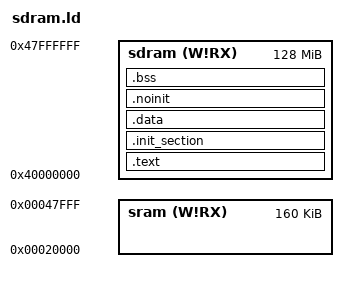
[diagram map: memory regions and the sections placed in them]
/****************************************************************************
 * boards/arm/t113/t113-evb/scripts/sdram.ld.S
 *
 * SPDX-License-Identifier: Apache-2.0
 *
 * Licensed to the Apache Software Foundation (ASF) under one or more
 * contributor license agreements.  See the NOTICE file distributed with
 * this work for additional information regarding copyright ownership.  The
 * ASF licenses this file to you under the Apache License, Version 2.0 (the
 * "License"); you may not use this file except in compliance with the
 * License.  You may obtain a copy of the License at
 *
 *   http://www.apache.org/licenses/LICENSE-2.0
 *
 * Unless required by applicable law or agreed to in writing, software
 * distributed under the License is distributed on an "AS IS" BASIS, WITHOUT
 * WARRANTIES OR CONDITIONS OF ANY KIND, either express or implied.  See the
 * License for the specific language governing permissions and limitations
 * under the License.
 *
 ****************************************************************************/

/* T113-S3 DDR linker script for NuttX AP binary.
 *
 * Standard layout: vectors at CONFIG_RAM_START (0x40000000), __start entry.
 * This binary is loaded to DDR by boot0 or xfel, no eGON header.
 */

MEMORY
{
    /* T113-S3 on-chip SRAM: 160KB (SRAM_A1 32K + DSP IRAM 64K + DSP DRAM0 32K + DSP DRAM1 32K)
     * Available at reset (DSP SRAM remapped to CPU by default).
     * Reserved for future use — no sections placed here yet.
     */
    sram  (W!RX) : ORIGIN = 0x00020000, LENGTH = 160K

    /* External DDR: 128MB at 0x40000000 */
    sdram (W!RX) : ORIGIN = 0x40000000, LENGTH = 128M
}

OUTPUT_FORMAT("elf32-littlearm", "elf32-littlearm", "elf32-littlearm")
OUTPUT_ARCH(arm)
ENTRY(_stext)

SECTIONS
{
    .text :
    {
        _stext = ABSOLUTE(.);
        *(.vectors)
        *(.text .text.*)
        *(.fixup)
        *(.gnu.warning)
        *(.rodata .rodata.*)
        *(.gnu.linkonce.t.*)
        *(.glue_7)
        *(.glue_7t)
        *(.got)
        *(.gcc_except_table)
        *(.gnu.linkonce.r.*)
        *(.ARM.extab*)
        *(.gnu.linkonce.armextab.*)
        PROVIDE_HIDDEN (__exidx_start = .);
        *(.ARM.exidx* .gnu.linkonce.armexidx.*)
        PROVIDE_HIDDEN (__exidx_end = .);
        _etext = ABSOLUTE(.);
    } > sdram

    .init_section :
    {
        _sinit = ABSOLUTE(.);
        KEEP(*(SORT_BY_INIT_PRIORITY(.init_array.*) SORT_BY_INIT_PRIORITY(.ctors.*)))
        KEEP(*(.init_array EXCLUDE_FILE(*crtbegin.o *crtbegin?.o *crtend.o *crtend?.o) .ctors))
        _einit = ABSOLUTE(.);
    } > sdram

    .data :
    {
        _sdata = ABSOLUTE(.);
        *(.data .data.*)
        *(.gnu.linkonce.d.*)
        CONSTRUCTORS
        . = ALIGN(4);
        _edata = ABSOLUTE(.);
    } > sdram

    .noinit :
    {
        _snoinit = ABSOLUTE(.);
        *(.noinit*)
        _enoinit = ABSOLUTE(.);
    } > sdram

    .bss :
    {
        _sbss = ABSOLUTE(.);
        *(.bss .bss.*)
        *(.gnu.linkonce.b.*)
        *(COMMON)
        . = ALIGN(8);
        _ebss = ABSOLUTE(.);
    } > sdram

    .stab 0 : { *(.stab) }
    .stabstr 0 : { *(.stabstr) }
    .stab.excl 0 : { *(.stab.excl) }
    .stab.exclstr 0 : { *(.stab.exclstr) }
    .stab.index 0 : { *(.stab.index) }
    .stab.indexstr 0 : { *(.stab.indexstr) }
    .comment 0 : { *(.comment) }
    .debug_abbrev 0 : { *(.debug_abbrev) }
    .debug_info 0 : { *(.debug_info) }
    .debug_line 0 : { *(.debug_line) }
    .debug_pubnames 0 : { *(.debug_pubnames) }
    .debug_aranges 0 : { *(.debug_aranges) }
}
